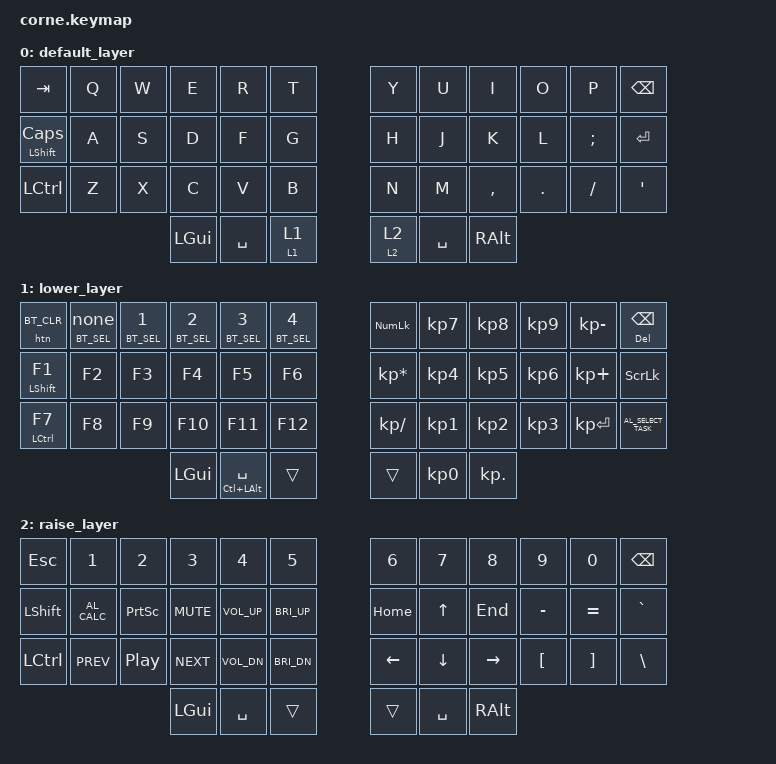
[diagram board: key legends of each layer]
/*
 * Copyright (c) 2020 The ZMK Contributors
 *
 * SPDX-License-Identifier: MIT
 */

#include <behaviors.dtsi>
#include <dt-bindings/zmk/keys.h>
#include <dt-bindings/zmk/bt.h>
/ {
    behaviors {
        mo_tog: behavior_mo_tog {
            compatible = "zmk,behavior-hold-tap";
            label = "mo_tog";
            #binding-cells = <2>;
            flavor = "hold-preferred";
            tapping-term-ms = <200>;
            bindings = <&mo>, <&tog>;
        };
        htn: behavior_htn {
            compatible = "zmk,behavior-hold-tap";
            label = "HOLD_TAP_NULL";
            #binding-cells = <2>;
            flavor = "hold-preferred";
            tapping-term-ms = <200>;
            bindings = <&bt>, <&none>;
	 };
	 sht: behavior_sht {
            compatible = "zmk,behavior-hold-tap";
            label = "HOLD_TAP";
            #binding-cells = <2>;
            flavor = "hold-preferred";
            tapping-term-ms = <200>;
            bindings = <&kp>, <&kp>;
        };
    };
};
/ {
        keymap {
                compatible = "zmk,keymap";

                default_layer {
// -----------------------------------------------------------------------------------------
// |  TAB |  Q  |  W  |  E  |  R  |  T  |   |  Y  |  U   |  I  |  O  |  P  | BKSP |
// |SHFTCP|  A  |  S  |  D  |  F  |  G  |   |  H  |  J   |  K  |  L  | ; : | ENT  |
// | CTRL |  Z  |  X  |  C  |  V  |  B  |   |  N  |  M   | , < | . > | / ? | ' "  |
//                    | GUI | SPC | LWR |   | RSE | SPC  | ALT |
                        bindings = <
   &kp TAB        &kp Q &kp W &kp E &kp R &kp T   &kp Y &kp U  &kp I     &kp O   &kp P    &kp BSPC
   &mt LSHFT CAPS &kp A &kp S &kp D &kp F &kp G   &kp H &kp J  &kp K     &kp L   &kp SEMI &kp RET
   &kp LCTRL      &kp Z &kp X &kp C &kp V &kp B   &kp N &kp M  &kp COMMA &kp DOT &kp FSLH &kp SQT
                 &kp LGUI &kp SPACE &mo_tog 1 1   &mo_tog 2 2  &kp SPACE &kp RALT
                        >;
                };
                lower_layer {
// -----------------------------------------------------------------------------------------
// |BTCLR | BT1 | BT2 | BT3 |  BT4  | BT5 |   |NMLCK|7HOME| 8UP |9PGUP|  -  | BKSP|
// |SHFTF1| F2  | F3  | F4  |  F5   | F6  |   |  *  |4LEFT|  5  |6RGHT|  +  |SCRLK|
// |CTRLF7| F8  | F9  | F10 |  F11  | F12 |   |  /  |1 END|2DOWN|3PGDN|ENT =| SEL |
//                    | GUI |C+A SPC|     |   |     |0NSRT| .DEL|
                        bindings = <
   &htn BT_CLR  &htn BT_SEL 0 &htn BT_SEL 1 &htn BT_SEL 2 &htn BT_SEL 3 &htn BT_SEL 4   &kp KP_NUM      &kp KP_N7 &kp KP_N8  &kp KP_N9 &kp KP_MINUS &sht DEL BSPC
   &mt LSHFT F1 &kp F2        &kp F3        &kp F4        &kp F5        &kp F6          &kp KP_MULTIPLY &kp KP_N4 &kp KP_N5  &kp KP_N6 &kp KP_PLUS &kp SLCK
   &mt LCTRL F7 &kp F8        &kp F9        &kp F10       &kp F11       &kp F12         &kp KP_DIVIDE   &kp KP_N1 &kp KP_N2  &kp KP_N3 &kp KP_ENTER &kp C_AL_SELECT_TASK
                          	                &kp LGUI &mt LC(LALT) SPACE &trans          &trans    &kp KP_N0  &kp KP_DOT
                        >;
                };

                raise_layer {
// -----------------------------------------------------------------------------------------
// | ESC | 1 ! | 2 @ | 3 # | 4 $ | 5 % |   | 6 ^ | 7 & | 8 * | 9 ( | 0 ) | BKSP |
// |SHFT | CALC|PSCRN|MUTE |VOLUP|BRIUP|   | HOME|  UP | END | - _ | = + | ` ~  |
// |CTRL | PREV|PLAYP|NEXT |VOLDN|BRIDN|   | LFT | DWN | RGT | [ { | ] } | \ |  |
//                    | GUI | SPC |     |   |     | SPC | ALT |
                        bindings = <
   &kp ESC   &kp N1        &kp N2     &kp N3     &kp N4        &kp N5         &kp N6   &kp N7    &kp N8    &kp N9    &kp N0    &kp BSPC
   &kp LSHFT &kp C_AL_CALC &kp PSCRN  &kp C_MUTE &kp C_VOL_UP  &kp C_BRI_UP   &kp HOME &kp UP    &kp END   &kp MINUS &kp EQUAL &kp GRAVE
   &kp LCTRL &kp C_PREV    &kp C_PP   &kp C_NEXT &kp C_VOL_DN  &kp C_BRI_DN   &kp LEFT &kp DOWN  &kp RIGHT &kp LBKT  &kp RBKT  &kp BSLH
                    	              &kp LGUI   &kp SPACE     &trans         &trans   &kp SPACE &kp RALT
                        >;
                };
        };
};
